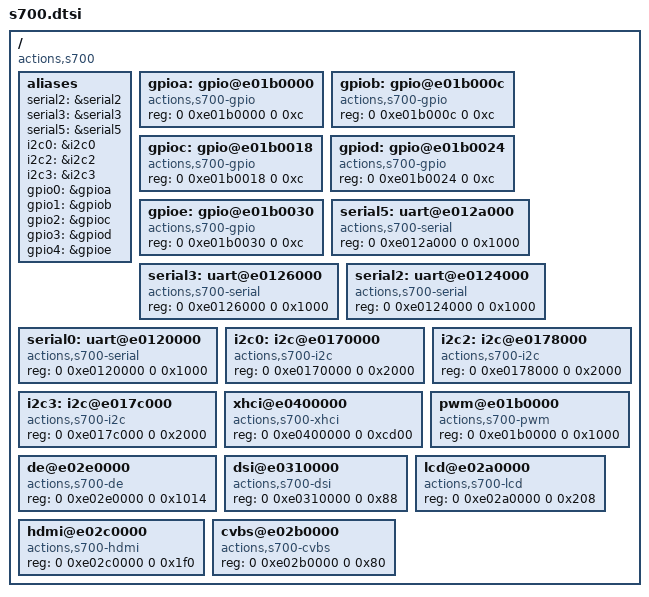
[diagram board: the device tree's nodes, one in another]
/*
 * Copyright (c) 2015 Actions Semi Co., Ltd.
 *
 * SPDX-License-Identifier:	GPL-2.0+
 */

/ {
	compatible = "actions,s700";
	#address-cells = <2>;
	#size-cells = <2>;

	aliases {
		serial2 = &serial2;
		serial3 = &serial3;
		serial5 = &serial5;
		i2c0 = &i2c0;
		i2c2 = &i2c2;
		i2c3 = &i2c3;
		gpio0 = &gpioa;
		gpio1 = &gpiob;
		gpio2 = &gpioc;
		gpio3 = &gpiod;
		gpio4 = &gpioe;
	};

	gpioa: gpio@e01b0000 {
		compatible = "actions,s700-gpio";
		reg = <0 0xe01b0000 0 0xc>;
		#gpio-cells = <2>;
	};
	gpiob: gpio@e01b000c {
		compatible = "actions,s700-gpio";
		reg = <0 0xe01b000c 0 0xc>;
		#gpio-cells = <2>;
	};
	gpioc: gpio@e01b0018 {
		compatible = "actions,s700-gpio";
		reg = <0 0xe01b0018 0 0xc>;
		#gpio-cells = <2>;
	};
	gpiod: gpio@e01b0024 {
		compatible = "actions,s700-gpio";
		reg = <0 0xe01b0024 0 0xc>;
		#gpio-cells = <2>;
	};
	gpioe: gpio@e01b0030 {
		compatible = "actions,s700-gpio";
		reg = <0 0xe01b0030 0 0xc>;
		#gpio-cells = <2>;
	};

	serial5: uart@e012a000 {
		compatible = "actions,s700-serial";
		reg = <0 0xe012a000 0 0x1000>;
	};

	serial3: uart@e0126000 {
		compatible = "actions,s700-serial";
		reg = <0 0xe0126000 0 0x1000>;
	};
	serial2: uart@e0124000 {
		compatible = "actions,s700-serial";
		reg = <0 0xe0124000 0 0x1000>;
	};
	serial0: uart@e0120000 {
		compatible = "actions,s700-serial";
		reg = <0 0xe0120000 0 0x1000>;
	};

	i2c0: i2c@e0170000 {
		compatible = "actions,s700-i2c";
		reg = <0 0xe0170000 0 0x2000>;
	};

	i2c2: i2c@e0178000 {
		compatible = "actions,s700-i2c";
		reg = <0 0xe0178000 0 0x2000>;
	};

	i2c3: i2c@e017c000 {
		compatible = "actions,s700-i2c";
		reg = <0 0xe017c000 0 0x2000>;
	};

	xhci@e0400000 {
		compatible = "actions,s700-xhci";
		reg = <0 0xe0400000 0 0xcd00>;
	};

	pwm@e01b0000 {
		compatible = "actions,s700-pwm";
		reg = <0 0xe01b0000 0 0x1000>;
		#pwm-cells = <3>;
	};

	de@e02e0000 {
		compatible = "actions,s700-de";
		reg = <0 0xe02e0000 0 0x1014>;
	};

	dsi@e0310000 {
		compatible = "actions,s700-dsi";
		reg = <0 0xe0310000 0 0x88>;
	};

	lcd@e02a0000 {
		compatible = "actions,s700-lcd";
		reg = <0 0xe02a0000 0 0x208>;
	};

	hdmi@e02c0000 {
		compatible = "actions,s700-hdmi";
		reg = <0 0xe02c0000 0 0x1f0>;
	};
	cvbs@e02b0000{
		 compatible = "actions,s700-cvbs";
		 reg = <0 0xe02b0000 0 0x80>;
		 };
};
